# MKM34Z7 register map
Vendor: Freescale Semiconductor, Inc.; Series: Kinetis_M; File version: 1.6
CPU: CM0PLUS r0p0, little endian, no MPU, no FPU, VTOR, 2 interrupt priority bits
Registers are 8-bit, read-write, reset 0x0 unless marked. A register's access mark holds for its fields unless they carry their own. Offsets are from the block's base; [hi:lo] are bit positions; {n}, {i} and the like mark numbered series; 'fields as' and 'values as' point back to an identical list.

## PORTA — Pin Control and Interrupts
Base 0x40046000; register names take the prefix PORTA_
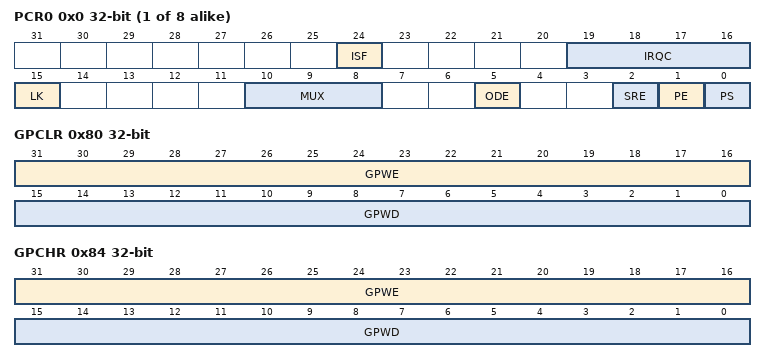
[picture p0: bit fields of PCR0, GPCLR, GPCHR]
{0x0+4i} PCR{i} (i=0..7) 32-bit — Pin Control Register n
  [24] ISF — Interrupt Status Flag
    0=Configured interrupt is not detected; 1=Configured interrupt is detected. If the pin is configured to generate a DMA request, then the corresponding flag will be cleared automatically at the completion of the requested DMA transfer. Otherwise, the flag remains set until a logic 1 is written to the flag. If the pin is configured for a level sensitive interrupt and the pin remains asserted, then the flag is set again immediately after it is cleared.
  [19:16] IRQC — Interrupt Configuration
    0=Interrupt Status Flag (ISF) is disabled; 1=ISF flag and DMA request on rising edge; 2=ISF flag and DMA request on falling edge; 3=ISF flag and DMA request on either edge; 8=ISF flag and Interrupt when logic 0; 9=ISF flag and Interrupt on rising-edge; 10=ISF flag and Interrupt on falling-edge; 11=ISF flag and Interrupt on either edge; 12=ISF flag and Interrupt when logic 1
  [15] LK — Lock Register
    0=Pin Control Register fields [15:0] are not locked; 1=Pin Control Register fields [15:0] are locked and cannot be updated until the next system reset
  [10:8] MUX — Pin Mux Control
    0=Pin disabled (analog); 1=Alternative 1 (GPIO); {v}=Alternative {v} (chip-specific) (v=2..7)
  [5] ODE — Open Drain Enable
    0=Open drain output is disabled on the corresponding pin; 1=Open drain output is enabled on the corresponding pin, if the pin is configured as a digital output
  [2] SRE — Slew Rate Enable
    0=Fast slew rate is configured on the corresponding pin, if the pin is configured as a digital output; 1=Slow slew rate is configured on the corresponding pin, if the pin is configured as a digital output
  [1] PE — Pull Enable
    0=Internal pullup or pulldown resistor is not enabled on the corresponding pin; 1=Internal pullup or pulldown resistor is enabled on the corresponding pin, if the pin is configured as a digital input
  [0] PS — Pull Select
    0=Internal pulldown resistor is enabled on the corresponding pin, if the corresponding PE field is set; 1=Internal pullup resistor is enabled on the corresponding pin, if the corresponding PE field is set
0x80 GPCLR 32-bit wo — Global Pin Control Low Register
  [31:16] GPWE — Global Pin Write Enable
    0=Corresponding Pin Control Register is not updated with the value in GPWD; 1=Corresponding Pin Control Register is updated with the value in GPWD
  [15:0] GPWD — Global Pin Write Data
0x84 GPCHR 32-bit wo — Global Pin Control High Register
  fields as GPCLR
0xA0 ISFR 32-bit — Interrupt Status Flag Register
  [31:0] ISF — Interrupt Status Flag
    values as PCR0.ISF

## PORTB — Pin Control and Interrupts
Base 0x40047000; register names take the prefix PORTB_
Registers as PORTA.

## PORTC — Pin Control and Interrupts
Base 0x40048000; register names take the prefix PORTC_
Registers as PORTA.

## PORTD — Pin Control and Interrupts
Base 0x40049000; register names take the prefix PORTD_
Registers as PORTA.

## PORTE — Pin Control and Interrupts
Base 0x4004A000; register names take the prefix PORTE_
Registers as PORTA; these are added or differ:
0xC0 DFER 32-bit — Digital Filter Enable Register
  [31:0] DFE — Digital Filter Enable
    0=Digital filter is disabled on the corresponding pin and output of the digital filter is reset to zero; 1=Digital filter is enabled on the corresponding pin, if the pin is configured as a digital input
0xC4 DFCR 32-bit — Digital Filter Clock Register
  [0] CS — Clock Source
    0=Digital filters are clocked by the bus clock; 1=Digital filters are clocked by the LPO clock
0xC8 DFWR 32-bit — Digital Filter Width Register
  [4:0] FILT — Filter Length

## PORTF — Pin Control and Interrupts
Base 0x4004B000; register names take the prefix PORTF_
Registers as PORTA.

## PORTG — Pin Control and Interrupts
Base 0x4004C000; register names take the prefix PORTG_
Registers as PORTA.

## PORTH — Pin Control and Interrupts
Base 0x4004D000; register names take the prefix PORTH_
Registers as PORTA.

## PORTI — Pin Control and Interrupts
Base 0x4004E000; register names take the prefix PORTI_
Registers as PORTA.

## PORTJ — Pin Control and Interrupts
Base 0x40037000; register names take the prefix PORTJ_
Registers as PORTA.

## PORTK — Pin Control and Interrupts
Base 0x40038000; register names take the prefix PORTK_
Registers as PORTA.

## PORTL — Pin Control and Interrupts
Base 0x40039000; register names take the prefix PORTL_
Registers as PORTA.

## PORTM — Pin Control and Interrupts
Base 0x4003A000; register names take the prefix PORTM_
Registers as PORTA.
